AUTOSAR XML (schema 00049)
package /Application/DltConfig
  dlt log channel to process mapping DltLogChannelToProcessMapping_MonitoringManager_TO_MonitoringManager: dlt-log-channel=MonitoringManager, process=MonitoringManager
package /Application/Executable
  executable MonitoringManager: category=APPLICATION_LEVEL, logging-behavior=USES-LOGGING, reporting-behavior=REPORTS-EXECUTION-STATE, version=1.0.0
    root sw component prototype AA: application-type=MonitoringManager
package /Application/Manifest
  5 x service instance to port prototype mapping:
    MonitoringManager_AA_PPortMonitoringManagement: port-prototype=AA.PPortMonitoringManagement, service-instance=EEVP_MonitoringManager_Provider_MonitoringManagement
    MonitoringManager_AA_RPortMoodLamp: port-prototype=AA.RPortMoodLamp, service-instance=EEVP_MonitoringManager_Consumer_MoodLamp
    MonitoringManager_AA_RPortOtaMonitoring: port-prototype=AA.RPortOtaMonitoring, service-instance=EEVP_MonitoringManager_Consumer_OtaMonitoring
    MonitoringManager_AA_RPortRearCurtain: port-prototype=AA.RPortRearCurtain, service-instance=EEVP_MonitoringManager_Consumer_RearCurtain
    MonitoringManager_AA_RPortStateManager: port-prototype=AA.RPortStateManager, service-instance=EEVP_MonitoringManager_Consumer_StateManager
package /Application/Process
  process MonitoringManager: executable=MonitoringManager, state-dependent-startup-config{execution-dependency=OTAClient.Running, function-group-state=MachineFG.Startup, resource-group=DefaultResourceGroup, startup-config=MonitoringManager}
    process state machine MonitoringManager: type=ProcessState
package /Application/StartupConfig
  startup config set EEVP_MonitoringManager_StartupConfig
    startup config MonitoringManager: scheduling-policy=SCHED_OTHER, scheduling-priority=0
package /Application/SwComponent
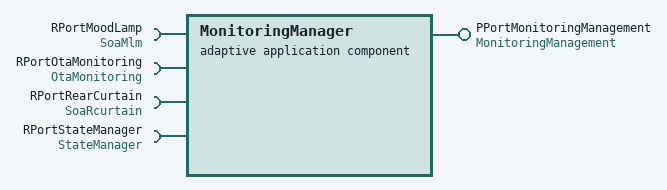
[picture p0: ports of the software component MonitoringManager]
  adaptive application sw component type MonitoringManager
    provide port PPortMonitoringManagement: provided-interface=MonitoringManagement
    4 x require port:
      RPortMoodLamp: required-interface=SoaMlm
      RPortOtaMonitoring: required-interface=OtaMonitoring
      RPortRearCurtain: required-interface=SoaRcurtain
      RPortStateManager: required-interface=StateManager
